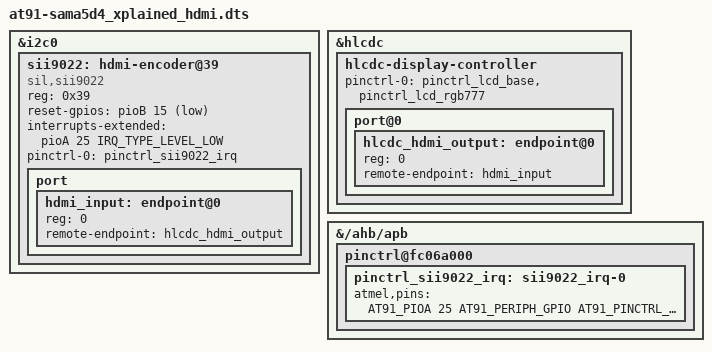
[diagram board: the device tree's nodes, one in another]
/*
 * Device Tree file for the SAMA5D4 Xplained board with HDMI
 *
 *  Copyright (C) 2017 Atmel Free Electrons
 *                Quentin Schulz <quentin.schulz@free-electrons.com>
 *
 * This file is dual-licensed: you can use it either under the terms
 * of the GPL or the X11 license, at your option. Note that this dual
 * licensing only applies to this file, and not this project as a
 * whole.
 *
 *  a) This file is free software; you can redistribute it and/or
 *     modify it under the terms of the GNU General Public License as
 *     published by the Free Software Foundation; either version 2 of the
 *     License, or (at your option) any later version.
 *
 *     This file is distributed in the hope that it will be useful,
 *     but WITHOUT ANY WARRANTY; without even the implied warranty of
 *     MERCHANTABILITY or FITNESS FOR A PARTICULAR PURPOSE.  See the
 *     GNU General Public License for more details.
 *
 * Or, alternatively,
 *
 *  b) Permission is hereby granted, free of charge, to any person
 *     obtaining a copy of this software and associated documentation
 *     files (the "Software"), to deal in the Software without
 *     restriction, including without limitation the rights to use,
 *     copy, modify, merge, publish, distribute, sublicense, and/or
 *     sell copies of the Software, and to permit persons to whom the
 *     Software is furnished to do so, subject to the following
 *     conditions:
 *
 *     The above copyright notice and this permission notice shall be
 *     included in all copies or substantial portions of the Software.
 *
 *     THE SOFTWARE IS PROVIDED "AS IS", WITHOUT WARRANTY OF ANY KIND,
 *     EXPRESS OR IMPLIED, INCLUDING BUT NOT LIMITED TO THE WARRANTIES
 *     OF MERCHANTABILITY, FITNESS FOR A PARTICULAR PURPOSE AND
 *     NONINFRINGEMENT. IN NO EVENT SHALL THE AUTHORS OR COPYRIGHT
 *     HOLDERS BE LIABLE FOR ANY CLAIM, DAMAGES OR OTHER LIABILITY,
 *     WHETHER IN AN ACTION OF CONTRACT, TORT OR OTHERWISE, ARISING
 *     FROM, OUT OF OR IN CONNECTION WITH THE SOFTWARE OR THE USE OR
 *     OTHER DEALINGS IN THE SOFTWARE.
 */

/dts-v1/;
/plugin/;

#include <dt-bindings/interrupt-controller/irq.h>
#include <dt-bindings/gpio/gpio.h>
#include <dt-bindings/pinctrl/at91.h>

/ {
	fragment@0 {
		target = <&i2c0>;
		__overlay__ {
			sii9022: hdmi-encoder@39 {
				compatible = "sil,sii9022";
				reg = <0x39>;
				reset-gpios = <&pioB 15 GPIO_ACTIVE_LOW>;
				interrupts-extended = <&pioA 25 IRQ_TYPE_LEVEL_LOW>;
				pinctrl-names = "default";
				pinctrl-0 = <&pinctrl_sii9022_irq>;

				port {
					#address-cells = <1>;
					#size-cells = <0>;

					hdmi_input: endpoint@0 {
						reg = <0>;
						remote-endpoint = <&hlcdc_hdmi_output>;
					};
				};
			};
		};
	};

	fragment@1 {
		target = <&hlcdc>;
		__overlay__ {
			status = "okay";

			hlcdc-display-controller {
				pinctrl-names = "default";
				pinctrl-0 = <&pinctrl_lcd_base &pinctrl_lcd_rgb777>;

				port@0 {
					hlcdc_hdmi_output: endpoint@0 {
						reg = <0>;
						remote-endpoint = <&hdmi_input>;
					};
				};
			};
		};
	};

	fragment@2 {
		target-path = "/ahb/apb";
		__overlay__ {
			pinctrl@fc06a000 {
				pinctrl_sii9022_irq: sii9022_irq-0 {
					atmel,pins =
						<AT91_PIOA 25 AT91_PERIPH_GPIO AT91_PINCTRL_PULL_UP_DEGLITCH>;
				};
			};
		};
	};
};
